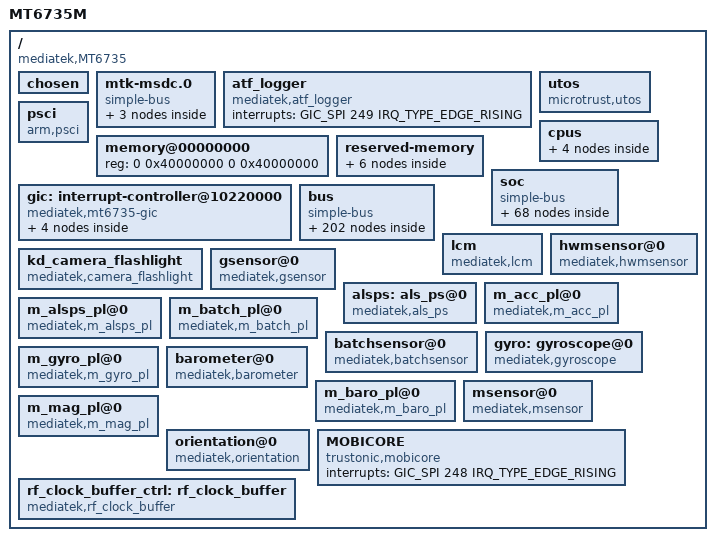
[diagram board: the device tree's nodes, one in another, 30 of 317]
/*
 * Mediatek's MT6735M SoC device tree source
 *
 * Copyright (c) 2013 MediaTek Co., Ltd.
 *              http://www.mediatek.com
 *
 */
#include <dt-bindings/interrupt-controller/arm-gic.h>
#include <dt-bindings/interrupt-controller/irq.h>
#include "mt6735m-pinfunc.h"
#include <dt-bindings/mmc/mt67xx-msdc.h>
#include <generated/autoconf.h>

/ {
	model = "MT6735M";
	compatible = "mediatek,MT6735";
	interrupt-parent = <&gic>;
	#address-cells = <2>;
	#size-cells = <2>;

	/* chosen */
		chosen {
			bootargs = "console=tty0 console=ttyMT0,921600n1 root=/dev/ram \
			initrd=0x44000000,0x1000000 loglevel=8 androidboot.hardware=mt6735";
		};

	/* Do not put any bus before mtk-msdc, because it should be mtk-msdc.0 for partition device node usage */
	/*workaround for .0*/
	mtk-msdc.0 {
				compatible = "simple-bus";
				#address-cells = <1>;
				#size-cells = <1>;
				ranges = <0 0 0 0xffffffff>;

				mmc0: msdc0@11230000{
						compatible = "mediatek,mt6735m-mmc";
						reg = <0x11230000 0x10000  /* MSDC0_BASE   */
							0x10000e84 0x2>;    /* FPGA PWR_GPIO, PWR_GPIO_EO */
						interrupts = <GIC_SPI 79 IRQ_TYPE_LEVEL_LOW>;
						status = "disabled";
				};

				mmc1: msdc1@11240000{
						compatible = "mediatek,mt6735m-mmc";
						reg = <0x11240000 0x10000  /* MSDC1_BASE   */
							0x10000e84 0x2>;    /* FPGA PWR_GPIO, PWR_GPIO_EO */
						interrupts = <GIC_SPI 80 IRQ_TYPE_LEVEL_LOW>;
						status = "disabled";
				};

	/* only used for old way of DCT, can be removed in new platform */
	msdc1_ins: default {
		compatible = "mediatek, msdc1_ins-eint";
	};
	};

	/* ATF logger SW IRQ number 281 = 32 + 249 */
	atf_logger {
		compatible = "mediatek,atf_logger";
		interrupts = <GIC_SPI 249 IRQ_TYPE_EDGE_RISING>;
	};

	utos {
		compatible = "microtrust,utos";
		interrupts = <GIC_SPI 244 IRQ_TYPE_EDGE_RISING>,
			<GIC_SPI 245 IRQ_TYPE_EDGE_RISING>,
			<GIC_SPI 246 IRQ_TYPE_EDGE_RISING>,
			<GIC_SPI 250 IRQ_TYPE_EDGE_RISING>,
			<GIC_SPI 251 IRQ_TYPE_EDGE_RISING>,
			<GIC_SPI 252 IRQ_TYPE_EDGE_RISING>,
			<GIC_SPI 253 IRQ_TYPE_EDGE_RISING>,
			<GIC_SPI 255 IRQ_TYPE_EDGE_RISING>;
	};

	psci {
		compatible	= "arm,psci";
		method		= "smc";
		cpu_suspend	= <0x84000001>;
		cpu_off		= <0x84000002>;
		cpu_on		= <0x84000003>;
		affinity_info	= <0x84000004>;
	};

	cpus {
		#address-cells = <1>;
		#size-cells = <0>;
/*		enable-method = "mediatek,mt6735-smp"; */

		cpu0: cpu@000 {
			device_type = "cpu";
			compatible = "arm,cortex-a53";
			reg = <0x000>;
			enable-method = "spin-table";
			cpu-release-addr = <0x0 0x40000200>;
			clock-frequency = <1000000000>;
		};

		cpu1: cpu@001 {
			device_type = "cpu";
			compatible = "arm,cortex-a53";
			reg = <0x001>;
			enable-method = "spin-table";
			cpu-release-addr = <0x0 0x40000200>;
			clock-frequency = <1000000000>;
		};

		cpu2: cpu@002 {
			device_type = "cpu";
			compatible = "arm,cortex-a53";
			reg = <0x002>;
			enable-method = "spin-table";
			cpu-release-addr = <0x0 0x40000200>;
			clock-frequency = <1000000000>;
		};

		cpu3: cpu@003 {
			device_type = "cpu";
			compatible = "arm,cortex-a53";
			reg = <0x003>;
			enable-method = "spin-table";
			cpu-release-addr = <0x0 0x40000200>;
			clock-frequency = <1000000000>;
		};
	};

	memory@00000000 {
		device_type = "memory";
		reg = <0 0x40000000 0 0x40000000>;
	};


		reserved-memory {
				#address-cells = <2>;
				#size-cells = <2>;
				ranges;

				/* reserve 192KB at DRAM start + 48MB */
				atf-reserved-memory@43000000 {
						compatible = "mediatek,mt6735-atf-reserved-memory",
						"mediatek,mt6735m-atf-reserved-memory",
						"mediatek,mt6753-atf-reserved-memory";
						no-map;
						reg = <0 0x43000000 0 0x30000>;
				};

		reserve-memory-ccci_md1 {
						compatible = "mediatek,reserve-memory-ccci_md1";
						no-map;
						size = <0 0x3810000>; // md_size+smem_size
						alignment = <0 0x2000000>;
						alloc-ranges = <0 0x40000000 0 0xC0000000>;
				};

				consys-reserve-memory {
						compatible = "mediatek,consys-reserve-memory";
						no-map;
						size = <0 0x100000>;
						alignment = <0 0x200000>;
				};

				ram_console-reserved-memory@43f00000 {
						compatible = "mediatek,ram_console";
						reg = <0 0x43f00000 0 0x10000>;
				};

				minirdump-reserved-memory@43ff0000 {
						compatible = "mediatek, minirdump";
						reg = <0 0x43ff0000 0 0x10000>;
				};

				pstore-reserved-memory@43f10000 {
						compatible = "mediatek,pstore";
						reg = <0 0x43f10000 0 0xe0000>;
				};
		};

		gic: interrupt-controller@10220000 {
				compatible = "mediatek,mt6735-gic";
				#interrupt-cells = <3>;
				#address-cells = <0>;
				interrupt-controller;
				reg = <0 0x10221000 0 0x1000>,
					<0 0x10222000 0 0x1000>,
					<0 0x10200620 0 0x1000>;

				mediatek,wdt_irq = <160>;

				gic-cpuif@0 {
					compatible = "arm,gic-cpuif";
					cpuif-id = <0>;
					cpu = <&cpu0>;
				};

				gic-cpuif@1 {
					compatible = "arm,gic-cpuif";
					cpuif-id = <1>;
					cpu = <&cpu1>;
				};

				gic-cpuif@2 {
					compatible = "arm,gic-cpuif";
					cpuif-id = <2>;
					cpu = <&cpu2>;
				};

				gic-cpuif@3 {
					compatible = "arm,gic-cpuif";
					cpuif-id = <3>;
					cpu = <&cpu3>;
				};

		};

	soc {
		compatible = "simple-bus";
		#address-cells = <1>;
		#size-cells = <1>;
		ranges = <0 0 0 0xffffffff>;

		cpuxgpt: cpuxgpt@10200000 {
			compatible = "mediatek,mt6735-cpuxgpt";
			reg = <0x10200000 0x1000>;
			interrupts = <GIC_SPI 64 IRQ_TYPE_LEVEL_HIGH>,
				<GIC_SPI 65 IRQ_TYPE_LEVEL_HIGH>,
				<GIC_SPI 66 IRQ_TYPE_LEVEL_HIGH>,
				<GIC_SPI 67 IRQ_TYPE_LEVEL_HIGH>,
				<GIC_SPI 68 IRQ_TYPE_LEVEL_HIGH>,
				<GIC_SPI 69 IRQ_TYPE_LEVEL_HIGH>,
				<GIC_SPI 70 IRQ_TYPE_LEVEL_HIGH>,
				<GIC_SPI 71 IRQ_TYPE_LEVEL_HIGH>;
		};

		apxgpt: apxgpt@10004000 {
			compatible = "mediatek,mt6735-apxgpt";
			reg = <0x10004000 0x1000>;
			interrupts = <GIC_SPI 152 IRQ_TYPE_LEVEL_LOW>;
			clock-frequency = <13000000>;
		};

		ledrgb: ledrgb {
			compatible = "mediatek,mt6735-led-rgb";
		};
		fingerprint: fingerprint {
			compatible = "mediatek,fingerprint";
		};

		hall_1: hall_1 {
			compatible = "mediatek,hall";
		};

		camera_flashlight: camera_flashlight {
			compatible = "mediatek,camera_flashlight";
		};


		pmu {
			compatible = "arm,cortex-a7-pmu";
			interrupts = <GIC_SPI 8 IRQ_TYPE_LEVEL_LOW>,
				<GIC_SPI 9 IRQ_TYPE_LEVEL_LOW>,
				<GIC_SPI 10 IRQ_TYPE_LEVEL_LOW>,
				<GIC_SPI 11 IRQ_TYPE_LEVEL_LOW>;
			interrupt-affinity = <&cpu0>,
					     <&cpu1>,
					     <&cpu2>,
					     <&cpu3>;
		};

		timer {
			compatible = "arm,armv8-timer";
			interrupts = <GIC_PPI 13 IRQ_TYPE_LEVEL_LOW>, /*Secure Physical Timer Event*/
				<GIC_PPI 14 IRQ_TYPE_LEVEL_LOW>, /*Non-Secure Physical Timer Event*/
				<GIC_PPI 11 IRQ_TYPE_LEVEL_LOW>, /*Virtual Timer Event*/
				<GIC_PPI 10 IRQ_TYPE_LEVEL_LOW>; /*Hypervisor Timer Event*/
				clock-frequency = <13000000>;
		};

		mt_pmic_regulator {
			compatible = "mediatek,mt_pmic";
			/*reg = <0x01>*/
			buck_regulators {
			compatible = "mediatek,mt_pmic_buck_regulators";
				mt_pmic_vpa_buck_reg: buck_vpa {
					regulator-name = "vpa";
					regulator-min-microvolt = <500000>;
					regulator-max-microvolt = <3650000>;
					regulator-ramp-delay = <50000>;
					regulator-enable-ramp-delay = <180>;
				};
				mt_pmic_vproc_buck_reg: buck_vproc {
					regulator-name = "vproc";
					regulator-min-microvolt = <600000>;
					regulator-max-microvolt = <1393750>;
					regulator-ramp-delay = <6250>;
					regulator-enable-ramp-delay = <180>;
					regulator-always-on;
					regulator-boot-on;
				};
				mt_pmic_vcore1_buck_reg: buck_vcore1 {
					regulator-name = "vcore1";
					regulator-min-microvolt = <600000>;
					regulator-max-microvolt = <1393750>;
					regulator-ramp-delay = <6250>;
					regulator-enable-ramp-delay = <180>;
					regulator-always-on;
					regulator-boot-on;
				};
				mt_pmic_vsys22_buck_reg: buck_vsys22 {
					regulator-name = "vsys22";
					regulator-min-microvolt = <1200000>;
					regulator-max-microvolt = <1993750>;
					regulator-ramp-delay = <6250>;
					regulator-enable-ramp-delay = <180>;
					regulator-always-on;
					regulator-boot-on;
				};
				mt_pmic_vlte_buck_reg: buck_vlte {
					regulator-name = "vlte";
					regulator-min-microvolt = <600000>;
					regulator-max-microvolt = <1393750>;
					regulator-ramp-delay = <6250>;
					regulator-enable-ramp-delay = <180>;
					regulator-always-on;
					regulator-boot-on;
				};
			};	/* End of buck_regulators */
			ldo_regulators {
				compatible = "mediatek,mt_pmic_ldo_regulators";
				mt_pmic_vaux18_ldo_reg: ldo_vaux18 {
					regulator-name = "vaux18";
					regulator-min-microvolt = <1800000>;
					regulator-max-microvolt = <1800000>;
					regulator-enable-ramp-delay = <264>;
					regulator-boot-on;
				};
				mt_pmic_vtcxo_0_ldo_reg: ldo_vtcxo_0 {
					regulator-name = "vtcxo_0";
					regulator-min-microvolt = <2800000>;
					regulator-max-microvolt = <2800000>;
					regulator-enable-ramp-delay = <110>;
					regulator-boot-on;
				};
				mt_pmic_vtcxo_1_ldo_reg: ldo_vtcxo_1 {
					regulator-name = "vtcxo_1";
					regulator-min-microvolt = <2800000>;
					regulator-max-microvolt = <2800000>;
					regulator-enable-ramp-delay = <110>;
				};
				mt_pmic_vaud28_ldo_reg: ldo_vaud28 {
					regulator-name = "vaud28";
					regulator-min-microvolt = <2800000>;
					regulator-max-microvolt = <2800000>;
					regulator-enable-ramp-delay = <264>;
					regulator-boot-on;
				};
				mt_pmic_vcn28_ldo_reg: ldo_vcn28 {
					regulator-name = "vcn28";
					regulator-min-microvolt = <2800000>;
					regulator-max-microvolt = <2800000>;
					regulator-enable-ramp-delay = <264>;
				};
				mt_pmic_vcama_ldo_reg: ldo_vcama {
					regulator-name = "vcama";
					regulator-min-microvolt = <1500000>;
					regulator-max-microvolt = <2800000>;
					regulator-enable-ramp-delay = <264>;
				};
				mt_pmic_vcn33_bt_ldo_reg: ldo_vcn33_bt {
					regulator-name = "vcn33_bt";
					regulator-min-microvolt = <3300000>;
					regulator-max-microvolt = <3600000>;
					regulator-enable-ramp-delay = <264>;
				};
				mt_pmic_vcn33_wifi_ldo_reg: ldo_vcn33_wifi {
					regulator-name = "vcn33_wifi";
					regulator-min-microvolt = <3300000>;
					regulator-max-microvolt = <3600000>;
					regulator-enable-ramp-delay = <264>;
				};
				mt_pmic_vusb33_ldo_reg: ldo_vusb33 {
					regulator-name = "vusb33";
					regulator-min-microvolt = <3300000>;
					regulator-max-microvolt = <3300000>;
					regulator-enable-ramp-delay = <264>;
					regulator-boot-on;
				};
				mt_pmic_vefuse_ldo_reg: ldo_vefuse {
					regulator-name = "vefuse";
					regulator-min-microvolt = <1800000>;
					regulator-max-microvolt = <2200000>;
					regulator-enable-ramp-delay = <264>;
				};
				mt_pmic_vsim1_ldo_reg: ldo_vsim1 {
					regulator-name = "vsim1";
					regulator-min-microvolt = <1700000>;
					regulator-max-microvolt = <2100000>;
					regulator-enable-ramp-delay = <264>;
				};
				mt_pmic_vsim2_ldo_reg: ldo_vsim2 {
					regulator-name = "vsim2";
					regulator-min-microvolt = <1700000>;
					regulator-max-microvolt = <2100000>;
					regulator-enable-ramp-delay = <264>;
				};
				mt_pmic_vemc33_ldo_reg: ldo_vemc_3v3 {
					regulator-name = "vemc_3v3";
					regulator-min-microvolt = <1800000>;
					regulator-max-microvolt = <3300000>;
					regulator-enable-ramp-delay = <264>;
					regulator-boot-on;
				};
				mt_pmic_vmch_ldo_reg: ldo_vmch {
					regulator-name = "vmch";
					regulator-min-microvolt = <2900000>;
					regulator-max-microvolt = <3300000>;
					regulator-enable-ramp-delay = <44>;
				};
				mt_pmic_vtref_ldo_reg: ldo_vtref {
					regulator-name = "vtref";
					regulator-min-microvolt = <1800000>;
					regulator-max-microvolt = <1800000>;
					regulator-enable-ramp-delay = <240>;
				};
				mt_pmic_vmc_ldo_reg: ldo_vmc {
					regulator-name = "vmc";
					regulator-min-microvolt = <1800000>;
					regulator-max-microvolt = <3300000>;
					regulator-enable-ramp-delay = <44>;
				};
				mt_pmic_vcam_af_ldo_reg: ldo_vcamaf {
					regulator-name = "vcamaf";
					regulator-min-microvolt = <1200000>;
					regulator-max-microvolt = <3300000>;
					regulator-enable-ramp-delay = <264>;
				};
				mt_pmic_vio28_ldo_reg: ldo_vio28 {
					regulator-name = "vio28";
					regulator-min-microvolt = <2800000>;
					regulator-max-microvolt = <2800000>;
					regulator-enable-ramp-delay = <264>;
					regulator-boot-on;
				};
				mt_pmic_vgp1_ldo_reg: ldo_vgp1 {
					regulator-name = "vgp1";
					regulator-min-microvolt = <1200000>;
					regulator-max-microvolt = <3300000>;
					regulator-enable-ramp-delay = <264>;
				};
				mt_pmic_vibr_ldo_reg: ldo_vibr {
					regulator-name = "vibr";
					regulator-min-microvolt = <1200000>;
					regulator-max-microvolt = <3300000>;
					regulator-enable-ramp-delay = <44>;
				};
				mt_pmic_vcamd_ldo_reg: ldo_vcamd {
					regulator-name = "vcamd";
					regulator-min-microvolt = <900000>;
					regulator-max-microvolt = <1500000>;
					regulator-enable-ramp-delay = <264>;
				};
				mt_pmic_vrf18_0_ldo_reg: ldo_vrf18_0 {
					regulator-name = "vrf18_0";
					regulator-min-microvolt = <1825000>;
					regulator-max-microvolt = <1825000>;
					regulator-enable-ramp-delay = <220>;
				};
				mt_pmic_vrf18_1_ldo_reg: ldo_vrf18_1 {
					regulator-name = "vrf18_1";
					regulator-min-microvolt = <1200000>;
					regulator-max-microvolt = <1825000>;
					regulator-enable-ramp-delay = <220>;
				};
				mt_pmic_vio18_ldo_reg: ldo_vio18 {
					regulator-name = "vio18";
					regulator-min-microvolt = <1800000>;
					regulator-max-microvolt = <1800000>;
					regulator-enable-ramp-delay = <264>;
					regulator-boot-on;
				};
				mt_pmic_vcn18_ldo_reg: ldo_vcn18 {
					regulator-name = "vcn18";
					regulator-min-microvolt = <1800000>;
					regulator-max-microvolt = <1800000>;
					regulator-enable-ramp-delay = <44>;
				};
				mt_pmic_vcam_io_ldo_reg: ldo_vcamio {
					regulator-name = "vcamio";
					regulator-min-microvolt = <1200000>;
					regulator-max-microvolt = <1800000>;
					regulator-enable-ramp-delay = <220>;
				};
				mt_pmic_vsram_ldo_reg: ldo_vsram {
					regulator-name = "vsram";
					regulator-min-microvolt = <700000>;
					regulator-max-microvolt = <1493750>;
					regulator-enable-ramp-delay = <220>;
					regulator-ramp-delay = <6250>;
					regulator-boot-on;
				};
				mt_pmic_vm_ldo_reg: ldo_vm {
					regulator-name = "vm";
					regulator-min-microvolt = <1240000>;
					regulator-max-microvolt = <1540000>;
					regulator-enable-ramp-delay = <264>;
					regulator-boot-on;
				};
			};/* End of ldo_regulators */
			regulators_supply {
				compatible = "mediatek,mt_pmic_regulator_supply";
				vaux18-supply = <&mt_pmic_vaux18_ldo_reg>;
				vtcxo_0-supply = <&mt_pmic_vtcxo_0_ldo_reg>;
				vtcxo_1-supply = <&mt_pmic_vtcxo_1_ldo_reg>;
				vaud28-supply = <&mt_pmic_vaud28_ldo_reg>;
				vefuse-supply = <&mt_pmic_vefuse_ldo_reg>;
				vsim1-supply = <&mt_pmic_vsim1_ldo_reg>;
				vsim2-supply = <&mt_pmic_vsim2_ldo_reg>;
				vemc_3v3-supply = <&mt_pmic_vemc33_ldo_reg>;
				vmch-supply = <&mt_pmic_vmch_ldo_reg>;
				vtref-supply = <&mt_pmic_vtref_ldo_reg>;
				vmc-supply = <&mt_pmic_vmc_ldo_reg>;
				vio28-supply = <&mt_pmic_vio28_ldo_reg>;
				vibr-supply = <&mt_pmic_vibr_ldo_reg>;
				vrf18_0-supply = <&mt_pmic_vrf18_0_ldo_reg>;
				vrf18_1-supply = <&mt_pmic_vrf18_1_ldo_reg>;
				vio18-supply = <&mt_pmic_vio18_ldo_reg>;
				vsram-supply = <&mt_pmic_vsram_ldo_reg>;
				vm-supply = <&mt_pmic_vm_ldo_reg>;

			};/* End of regulators_supply */
		};/* End of mt_pmic_regulator */
		toprgu: toprgu@10212000 {
			compatible = "mediatek,mt6735-rgu";
			reg = <0x10212000 0x1000>;
			interrupts = <GIC_SPI 128 IRQ_TYPE_EDGE_FALLING>;
		};

		mcu_biu: mcu_biu@10300000 {
			compatible = "mediatek,mt6735-mcu_biu";
			reg = <0x10300000 0x8000>;
		};

		gpio_usage_mapping:gpio {
			compatible = "mediatek,gpio_usage_mapping";
		};

		gpio: gpio@10211000 {
			compatible = "mediatek,gpio";
			reg = <0x10211000 0x1000>;
		};

		dramc_nao: dramc_nao@1020e000 {
			compatible = "mediatek,mt6735-dramc_nao";
			reg = <0x1020e000 0x1000>;
		};

		ddrphy: ddrphy@10213000 {
			compatible = "mediatek,mt6735-ddrphy";
			reg = <0x10213000 0x1000>;
		};

		dramc: dramc@10214000 {
			compatible = "mediatek,mt6735-dramc";
			reg = <0x10214000 0x1000>;
			/*clocks = <&infrasys INFRA_GCE>;*/
			clock-names = "infra-cqdma";
		};

		keypad: keypad@10003000 {
			compatible = "mediatek,mt6735-keypad",
					"mediatek,mt6735m-keypad";
			reg = <0x10003000 0x1000>;
			interrupts = <GIC_SPI 164 IRQ_TYPE_EDGE_FALLING>;
		};

		apirtx:irtx@11011000 {
			compatible = "mediatek,irtx";
			reg = <0x11011000 0x1000>;
			interrupts = <GIC_SPI 124 IRQ_TYPE_LEVEL_HIGH>;
			pwm_ch = <0>;
		};

		apuart0: apuart0@11002000 {
			cell-index = <0>;
			compatible = "mediatek,mt6735-uart";
			reg = <0x11002000 0x1000>, /* UART base */
				  <0x11000380 0x1000>, /* DMA Tx base */
				  <0x11000400 0x80>; /* DMA Rx base */
			interrupts = <GIC_SPI 91 IRQ_TYPE_LEVEL_LOW>, /* UART IRQ */
						 <GIC_SPI 103 IRQ_TYPE_LEVEL_LOW>, /* DMA Tx IRQ */
						 <GIC_SPI 104 IRQ_TYPE_LEVEL_LOW>; /* DMA Rx IRQ */
		};

		apuart1: apuart1@11003000 {
			cell-index = <1>;
			compatible = "mediatek,mt6735-uart";
			reg = <0x11003000 0x1000>, /* UART base */
				  <0x11000480 0x80>, /* DMA Tx base */
				  <0x11000500 0x80>; /* DMA Rx base */
			interrupts = <GIC_SPI 92 IRQ_TYPE_LEVEL_LOW>, /* UART IRQ */
						 <GIC_SPI 105 IRQ_TYPE_LEVEL_LOW>, /* DMA Tx IRQ */
						 <GIC_SPI 106 IRQ_TYPE_LEVEL_LOW>; /* DMA Rx IRQ */
		};

		apuart2: apuart2@11004000 {
			cell-index = <2>;
			compatible = "mediatek,mt6735-uart";
			reg = <0x11004000 0x1000>, /* UART base */
				  <0x11000580 0x80>, /* DMA Tx base */
				  <0x11000600 0x80>; /* DMA Rx base */
			interrupts = <GIC_SPI 93 IRQ_TYPE_LEVEL_LOW>, /* UART IRQ */
						 <GIC_SPI 107 IRQ_TYPE_LEVEL_LOW>, /* DMA Tx IRQ */
						 <GIC_SPI 108 IRQ_TYPE_LEVEL_LOW>; /* DMA Rx IRQ */
		};

		apuart3: apuart3@11005000 {
			cell-index = <3>;
			compatible = "mediatek,mt6735-uart";
			reg = <0x11005000 0x1000>, /* UART base */
				  <0x11000680 0x80>, /* DMA Tx base */
				  <0x11000700 0x80>; /* DMA Rx base */
			interrupts = <GIC_SPI 94 IRQ_TYPE_LEVEL_LOW>, /* UART IRQ */
						 <GIC_SPI 109 IRQ_TYPE_LEVEL_LOW>, /* DMA Tx IRQ */
						 <GIC_SPI 110 IRQ_TYPE_LEVEL_LOW>; /* DMA Rx IRQ */
		};
		spi0:spi@1100a000 {
			compatible = "mediatek,mt6735m-spi";
			cell-index = <0>;
			spi-padmacro = <0>;
			reg = <0x1100a000 0x1000>;
			interrupts = <GIC_SPI 118 IRQ_TYPE_LEVEL_LOW>;
		};

		btif_tx:btif_tx@11000780 {
			compatible = "mediatek,btif_tx";
			reg = <0x11000780 0x80>;
			interrupts = <GIC_SPI 111 IRQ_TYPE_LEVEL_LOW>;
		};
		btif_rx:btif_rx@11000800 {
			compatible = "mediatek,btif_rx";
			reg = <0x11000800 0x80>;
			interrupts = <GIC_SPI 112 IRQ_TYPE_LEVEL_LOW>;
		};
		btif:btif@1100c000 {
			compatible = "mediatek,btif";
			reg = <0x1100c000 0x1000>;
			interrupts = <GIC_SPI 90 IRQ_TYPE_LEVEL_LOW>;
		};/* End of btif */

		consys:consys@18070000 {
			compatible = "mediatek,mt6735m-consys",
						 "mediatek,mt6735-consys";
			reg = <0x18070000 0x0200>,  /*CONN_MCU_CONFIG_BASE      */
			      <0x10212000 0x0100>,  /*AP_RGU_BASE               */
			      <0x10000000 0x2000>,  /*TOPCKGEN_BASE             */
			      <0x10006000 0x1000>;  /*SPM_BASE                  */
			interrupts = <GIC_SPI 227 IRQ_TYPE_LEVEL_LOW>, /* BGF_EINT */
						 <GIC_SPI 225 IRQ_TYPE_LEVEL_LOW>; /* WDT_EINT */
			vcn18-supply = <&mt_pmic_vcn18_ldo_reg>;
			vcn28-supply = <&mt_pmic_vcn28_ldo_reg>;
			vcn33_bt-supply = <&mt_pmic_vcn33_bt_ldo_reg>;
			vcn33_wifi-supply = <&mt_pmic_vcn33_wifi_ldo_reg>;
		};

		hacc:hacc@10008000 {
			compatible = "mediatek,hacc";
			reg = <0x10008000 0x1000>;
			interrupts = <GIC_SPI 174 IRQ_TYPE_LEVEL_LOW>;
		};
		als: als {
			compatible = "mediatek, als-eint";
		};

		gse_1: gse_1 {
			compatible = "mediatek, gse_1-eint";
			status = "disabled";
		};
		ext_buck_oc: ext_buck_oc {
			compatible = "mediatek, ext_buck_oc-eint";
			status = "disabled";
		};
		swtp: swtp {
			compatible = "mediatek, swtp-eint";
		};
	};

	bus {
		compatible = "simple-bus";
		#address-cells = <1>;
		#size-cells = <1>;
		ranges = <0 0 0 0xffffffff>;

		INFRACFG_AO@0x10000000 {
			compatible = "mediatek,INFRACFG_AO";
			reg = <0x10000000 0x1000>;
		};

		usb2jtag: usb2jtag@10000000 {
			compatible = "mediatek,usb2jtag_v1";
			reg = <0x10000000 0x1000>, <0x11210000 0x1000>;
		};

		PWRAP@0x10001000 {
			compatible = "mediatek,PWRAP";
			reg = <0x10001000 0x1000>;
			interrupts = <0 163 0x4>;
		};

		PERICFG@0x10002000 {
			compatible = "mediatek,PERICFG";
			reg = <0x10002000 0x1000>;
		};

		FHCTL@0x10209F00 {
			compatible = "mediatek,FHCTL";
			reg = <0x10209F00 0x100>;
		};
		KP@0x10003000 {
			compatible = "mediatek,KP";
			reg = <0x10003000 0x1000>;
			interrupts = <0 164 0x2>;
		};



		eintc: eintc@10005000 {
			compatible = "mediatek,mt-eic";
			reg = <0x10005000 0x1000>;
			interrupts = <GIC_SPI 153 IRQ_TYPE_LEVEL_HIGH>;

			#interrupt-cells = <2>;
			interrupt-controller;

			mediatek,max_eint_num = <213>;
			mediatek,mapping_table_entry = <0>;

			mediatek,debtime_setting_entry = <10>;
			mediatek,debtime_setting_array	= <0 125>,
							<1 250>,
							<2 500>,
							<3 1000>,
							<4 16000>,
							<5 32000>,
							<6 64000>,
							<7 128000>,
							<8 256000>,
							<9 512000>;
		};

				SLEEP@0x10006000 {
						compatible = "mediatek,SLEEP";
						reg = <0x10006000 0x1000>;
						interrupts = <0 165 0x8>,
												 <0 166 0x8>,
												 <0 167 0x8>,
												 <0 168 0x8>;
				};

		DEVAPC_AO@10007000 {
			compatible = "mediatek,DEVAPC_AO";
			reg = <0x10007000 0x1000>;
		};

		RSVD@0x10009000 {
			compatible = "mediatek,RSVD";
			reg = <0x10009000 0x1000>;
		};


		bat_meter: bat_meter {
			compatible = "mediatek,bat_meter";
			/* cust_battery_meter.h */
			/* ADC resistor  */
			r_bat_sense = <4 >;
			r_i_sense = <4 >;
			r_charger_1 = <330 >;
			r_charger_2 = <39 >;
			temperature_t0 = <110 >;
			temperature_t1 = <0 >;
			temperature_t2 = <25 >;
			temperature_t3 = <50 >;
			temperature_t = <255 >;	/* this should be fixed, never change the value */
			fg_meter_resistance = <0 >;

			/* Qmax for 0mA */
			q_max_pos_50 = <2409 >;
			q_max_pos_25 = <2331 >;
			q_max_pos_0 = <2391 >;
			q_max_neg_10 = <2390 >;
			/* Qmax for 400mA, said high current */
			q_max_pos_50_h_current = <2392 >;
			q_max_pos_25_h_current = <2285 >;
			q_max_pos_0_h_current = <1733 >;
			q_max_neg_10_h_current = <1355 >;
			/* Discharge percentage, 1: D5, 0: D2 */
			oam_d5 = <1 >;

			change_tracking_point = <1 >;
			/* SW OCV tracking setting */
			cust_tracking_point = <1 >;
			cust_r_sense = <68 >;
			cust_hw_cc = <0 >;
			aging_tuning_value = <103 >;
			cust_r_fg_offset = <0 >;
			ocv_board_compesate = <0 >;
			r_fg_board_base = <1000 >;
			r_fg_board_slope = <1000 >;
			car_tune_value = <92 >;

			/* HW Fuel gague  */
			current_detect_r_fg = <10 >;	/* Unit: mA */
			minerroroffset = <1000 >;
			fg_vbat_average_size = <18 >;
			r_fg_value = <10 >;	/* Unit: mOhm */

			cust_poweron_delta_capacity_tolrance = <30 >;
			cust_poweron_low_capacity_tolrance = <5 >;
			cust_poweron_max_vbat_tolrance = <90 >;
			cust_poweron_delta_vbat_tolrance = <30 >;
			cust_poweron_delta_hw_sw_ocv_capacity_tolrance = <10 >;

			/* Fixed battery temperature */
			fixed_tbat_25 = <1 >;
			/* Dynamic change wake up period of battery thread when suspend */
			vbat_normal_wakeup = <3600 >;	/* Unit: mV */
			vbat_low_power_wakeup = <3500 >;	/* Unit: mV */
			normal_wakeup_period = <5400 >;	/* Unit: second */
			low_power_wakeup_period = <300 >;	/* Unit: second */
			close_poweroff_wakeup_period = <30 >;	/* Unit: second */

			rbat_pull_up_r = <16900 >;
			rbat_pull_up_volt = <1800 >;


			batt_temperature_table_num = <17 >;
			batt_temperature_table = <
			    (-20) 68237
			    (-15) 53650
			    (-10) 42506
			    (-5) 33892
			    0 27219
			    5 22021
			    10 17926
			    15 14674
			    20 12081
			    25 10000 30 8315 35 6948 40 5834 45 4917 50 4161 55 3535 60 3014 >;
			battery_profile_t0_num = <100 >;
			battery_profile_t0 = <0	4312
				1	4284
				2	4253
				3	4240
				4	4229
				5	4214
				6	4204
				7	4193
				8	4169
				9	4157
				10	4148
				11	4136
				12	4133
				13	4117
				14	4105
				15	4096
				16	4091
				17	4086
			    18	4079
			    19	4048
			    20	4036
			    21	4028
			    22	4020
			    23	4003
			    24	3978
			    25	3973
			    26	3968
			    27	3965
			    28	3960
			    29	3951
			    30	3947
			    31	3943
			    32	3940
			    33	3931
			    34	3906
			    35	3895
			    36	3886
			    37	3883
			    38	3879
			    39	3873
			    40	3868
			    41	3864
			    42	3860
			    43	3857
			    44	3849
			    45	3845
			    46	3843
			    47	3838
			    48	3834
			    49	3827
			    50	3821
			    51	3816
			    52	3811
			    53	3807
			    55	3800
			    56	3798
			    57	3796
			    58	3793
			    59	3790
			    60	3788
			    61	3788
			    62	3785
			    63	3785
			    64	3780
			    65	3779
			    66	3777
			    67	3776
			    68	3771
			    69	3769
			    70	3767
			    71	3766
			    72	3765
			    73	3761
			    74	3760
			    75	3759
			    76	3756
			    77	3751
			    78	3743
			    79	3740
			    80	3738
			    81	3733
			    82	3724
			    83	3721
			    84	3717
			    85	3713
			    86	3712
			    87	3705
			    88	3702
			    89	3695
			    90	3689
			    91	3684
			    92	3676
			    93	3663
			    94	3651
			    95	3638
			    96	3626
			    97	3612
			    98	3566
			    99	3523
			    100 3500 >;
			battery_profile_t1_num = <100 >;
			battery_profile_t1 = <0	4333
				1	4312
				2	4296
				3	4270
				4	4258
				5	4247
				6	4237
				7	4227
				8	4208
				9	4198
				10	4188
				11	4179
				12	4160
				13	4152
			    14	4143
			    15	4133
			    16	4125
			    17	4111
			    18	4103
			    19	4097
			    20	4090
			    21	4082
			    22	4070
			    23	4044
			    24	4031
			    25	4019
			    26	4008
			    27	3989
			    28	3982
			    29	3974
			    30	3968
			    31	3962
			    32	3956
			    33	3945
			    34	3938
			    35	3931
			    36	3925
			    37	3912
			    38	3905
			    39	3899
			    40	3894
			    41	3888
			    42	3883
			    43	3872
			    44	3867
			    45	3862
			    46	3858
			    47	3848
			    48	3844
			    49	3841
			    50	3837
			    51	3834
			    52	3827
			    53	3823
			    54	3819
			    55	3817
			    56	3814
			    57	3811
			    58	3808
			    59	3806
			    60	3805
			    61	3803
			    62	3801
			    63	3798
			    64	3797
			    65	3795
			    66	3793
			    67	3790
			    68	3788
			    69	3787
			    70	3786
			    71	3783
			    72	3782
			    73	3779
			    74	3776
			    75	3774
			    76	3771
			    77	3765
			    78	3761
			    80	3755
			    81	3751
			    82	3744
			    83	3740
			    84	3734
			    85	3729
			    86	3724
			    87	3714
			    88	3709
			    89	3705
			    90	3702
			    91	3699
			    92	3693
			    93	3689
			    94	3683
			    95	3674
			    96	3662
			    97	3611
			    98	3573
			    99	3521
			    100 3500 >;
			battery_profile_t2_num = <100 >;
			battery_profile_t2 = <0 4329
			    2   4303
			    4   4282
			    5   4261
			    7   4241
			    9   4221
			    11  4202
			    13  4183
			    15  4164
			    16  4146
			    18  4127
			    20  4109
			    22  4091
			    24  4076
			    25  4067
			    27  4048
			    29  4017
			    31  3993
			    33  3979
			    34  3971
			    36  3963
			    38  3951
			    40  3937
			    42  3920
			    44  3900
			    45  3883
			    47  3869
			    49  3858
			    51  3847
			    53  3839
			    54  3830
			    56  3823
			    58  3816
			    60  3809
			    62  3803
			    64  3797
			    65  3792
			    67  3787
			    69  3783
			    71  3778
			    73  3772
			    74  3765
			    76  3758
			    78  3751
			    80  3745
			    82  3739
			    84  3731
			    85  3720
			    87  3710
			    89  3696
			    91  3689
			    93  3688
			    94  3685
			    96  3676
			    98  3620
			    100 3500
			    100 3500
			    100 3500
			    100 3500
                100 3500
			    100 3500
			    100 3500
			    100 3500
			    100 3500
			    100 3500
			    100 3500
			    100 3500
			    100 3500
			    100 3500
			    100 3500
			    100 3500
			    100 3500
			    100 3500
			    100 3500
			    100 3500
			    100 3500
			    100 3500
			    100 3500
			    100 3500
			    100 3500
			    100 3500
			    100 3500
			    100 3500
			    100 3500
			    100 3500
			    100 3500
			    100 3500
			    100 3500
			    100 3500
			    100 3500
			    100 3500
			    100 3500
			    100 3500
			    100 3500
			    100 3500
			    100 3500
			    100 3500
			    100 3500
			    100 3500
			    100 3500 >;
			battery_profile_t3_num = <100 >;
			battery_profile_t3 = <0 4339
				1   4327
				2   4315
				3   4294
				4   4284
				5   4275
			    6   4265
			    7   4246
			    8   4236
			    9   4227
			    10  4218
			    11  4209
			    12  4200
			    13  4182
			    14  4173
			    15  4163
			    16  4154
			    17  4136
			    18  4128
			    19  4120
			    20  4111
			    21  4094
			    22  4086
			    23  4076
			    24  4069
			    25  4061
			    26  4045
			    27  4039
			    28  4031
			    29  4022
			    30  4013
			    31  3999
			    32  3993
			    33  3987
			    34  3979
			    35  3973
			    36  3961
			    37  3955
			    38  3948
			    39  3941
			    40  3935
			    41  3924
			    42  3916
			    43  3906
			    44  3896
			    45  3878
			    46  3872
			    47  3865
			    48  3860
			    49  3854
			    50  3850
			    51  3842
			    52  3838
			    53  3834
			    54  3829
			    55  3822
			    56  3818
			    57  3814
			    58  3812
			    59  3810
			    60  3802
			    61  3798
			    62  3796
			    63  3793
			    64  3791
			    65  3786
			    66  3785
			    68  3780
			    69  3777
			    70  3772
			    71  3769
			    72  3765
			    73  3759
			    74  3751
			    75  3743
			    76  3739
			    77  3736
			    78  3733
			    79  3729
			    80  3723
			    81  3721
			    82  3717
			    83  3714
			    84  3707
			    85  3702
			    86  3697
			    87  3692
			    88  3687
			    89	3674
			    90  3672
			    91  3671
			    92  3671
			    93  3669
			    94  3667
			    95  3666
			    96  3659
			    97  3648
			    98  3590
			    99  3550
			    100 3500 >;

			r_profile_t0_num = <100 >;
			r_profile_t0 = <416  4312
				416  4284
				368  4253
				337  4240
				318  4229
				483  4214
				489  4204
				452  4193
				517  4169
				646  4157
				465  4148
				624  4136
				461  4133
				361  4117
				532  4105
				626  4096
				502  4091
				434  4086
				386  4079
				618  4048
				491  4036
				422  4028
				374  4020
				403  4003
				534  3978
				446  3973
				393  3968
				354  3965
				328  3960
				288  3951
				274  3947
				264  3943
				254  3940
				258  3931
				543  3906
			    653  3895
			    747  3886
			    787  3883
			    547  3879
			    411  3873
			    366  3868
			    333  3864
			    310  3860
			    291  3857
			    261  3849
			    251  3845
			    242  3843
			    233  3838
			    227  3834
			    231  3827
			    422  3821
			    584  3816
			    510  3811
			    667  3807
			    484  3800
			    434  3798
			    398  3796
			    473  3793
			    496  3790
			    440  3788
			    401  3788
			    520  3785
			    439  3785
			    526  3780
			    461  3779
			    414  3777
			    489  3776
			    803  3771
			    681  3769
			    571  3767
			    501  3766
			    452  3765
			    386  3761
			    363  3760
			    345  3759
			    465  3756
			    614  3751
			    851  3743
			    729  3740
			    611  3738
			    687  3733
			    735  3724
			    656  3721
			    779  3717
			    726  3713
			    634  3712
			    791  3705
			    486  3702
			    695  3695
			    842  3689
			    759  3684
			    661  3676
			    865  3663
			    995  3651
			    948  3638
			    818  3626
			    746  3612
			    664  3566
			    867  3523
			    1048 3500 >;

			r_profile_t1_num = <100 >;
			r_profile_t1 = <770  4333
				770  4312
				848  4296
				875  4270
				880  4258
				878  4247
				878  4237
				880  4227
				878  4208
				878  4198
				875  4188
				875  4179
				873  4160
				873  4152
				875  4143
				868  4133
				865  4125
				873  4111
				868  4103
				870  4097
				868  4090
				873  4082
				865  4070
				850  4044
				842  4031
				838  4019
				838  4008
				830  3989
				835  3982
				830  3974
				833  3968
				835  3962
			    835  3956
			    835  3945
			    833  3938
			    830  3931
			    830  3925
			    828  3912
			    823  3905
			    823  3899
			    825  3894
			    825  3888
			    825  3883
			    825  3872
			    830  3867
			    828  3862
			    828  3858
			    828  3848
			    833  3844
			    835  3841
			    838  3837
			    840  3834
			    848  3827
			    845  3823
			    848  3819
			    853  3817
			    855  3814
			    863  3811
			    865  3808
			    865  3806
			    873  3805
			    878  3803
			    880  3801
			    885  3798
			    893  3797
			    898  3795
			    898  3793
			    905  3790
			    913  3788
			    918  3787
			    928  3786
			    930  3783
			    940  3782
			    955  3779
			    965  3776
			    975  3774
			    980  3771
			    1003 3765
			    1008 3761
			    1038 3755
			    1050 3751
			    1083 3744
			    1098 3740
			    1113 3734
			    1133 3729
			    1150 3724
			    1200 3714
			    1225 3709
			    1253 3705
			    1288 3702
			    1315 3699
			    1390 3693
			    1433 3689
			    1473 3683
			    1513 3674
			    1558 3662
			    1625 3611
			    1665 3573
			    1703 3521
			    1750 3500 >;

			r_profile_t2_num = <100 >;
			r_profile_t2 = <204 4329
			    204 4303
			    209 4282
			    207 4261
			    207 4241
			    207 4221
			    207 4202
			    209 4183
			    209 4164
			    211 4146
			    211 4127
			    213 4109
			    216 4091
			    218 4076
			    231 4067
			    233 4048
			    224 4017
			    222 3993
			    229 3979
			    233 3971
			    240 3963
			    238 3951
			    236 3937
			    227 3920
			    211 3900
			    204 3883
			    202 3869
			    200 3858
			    198 3847
			    200 3839
			    200 3830
			    202 3823
			    202 3816
			    204 3809
			    207 3803
			    207 3797
			    209 3792
			    209 3787
			    211 3783
			    213 3778
			    209 3772
			    204 3765
			    202 3758
			    202 3751
			    202 3745
			    204 3739
			    209 3731
			    209 3720
			    213 3710
			    216 3696
			    216 3689
			    227 3688
			    238 3685
			    256 3676
			    262 3620
			    284 3500
			    336 3500
			    336 3500
			    336 3500
			    336 3500
				336 3500
			    336 3500
			    336 3500
			    336 3500
			    336 3500
			    336 3500
			    336 3500
			    336 3500
			    336 3500
			    336 3500
			    336 3500
			    336 3500
			    336 3500
			    336 3500
			    336 3500
			    336 3500
			    336 3500
			    336 3500
			    336 3500
			    336 3500
			    336 3500
			    336 3500
				336 3500
			    336 3500
			    336 3500
			    336 3500
			    336 3500
			    336 3500
			    336 3500
			    336 3500
			    336 3500
			    336 3500
			    336 3500
			    336 3500
			    336 3500
			    336 3500
			    336 3500
			    336 3500
			    336 3500
			    336 3500 >;

			r_profile_t3_num = <100 >;
			r_profile_t3 = <100 4339
				100 4327
				100 4315
				98  4294
				100 4284
				103 4275
			    103 4265
			    103 4246
			    103 4236
			    105 4227
			    103 4218
			    103 4209
			    108 4200
			    108 4182
			    110 4173
			    105 4163
			    105 4154
			    103 4136
			    105 4128
			    110 4120
			    110 4111
			    110 4094
			    108 4086
			    105 4076
			    105 4069
			    108 4061
			    108 4045
			    112 4039
			    110 4031
			    110 4022
			    113 4013
			    110 3999
			    113 3993
			    115 3987
			    110 3979
			    115 3973
			    118 3961
			    120 3955
			    118 3948
			    115 3941
			    115 3935
			    123 3924
			    120 3916
			    115 3906
			    110 3896
			    103 3878
			    108 3872
			    105 3865
			    105 3860
			    103 3854
			    100 3850
			    105 3842
			    105 3838
			    108 3834
			    103 3829
			    103 3822
			    103 3818
			    105 3814
			    105 3812
			    110 3810
			    105 3802
			    103 3798
			    105 3796
			    105 3793
			    105 3791
			    108 3786
			    113 3785
			    113 3780
			    110 3777
			    110 3772
			    110 3769
			    105 3765
			    105 3759
			    105 3751
			    103 3743
			    103 3739
			    103 3736
			    108 3733
			    105 3729
			    103 3723
			    108 3721
			    103 3717
			    103 3714
			    110 3707
			    108 3702
			    105 3697
			    105 3692
			    103 3687
			    105 3674
			    105 3672
			    108 3671
			    110 3671
			    108 3669
			    113 3667
			    115 3666
			    108 3659
			    110 3648
			    113 3590
			    115 3550
			    115 3500 >;
		};

		bat_notify: bat_notify {
			compatible = "mediatek,bat_notify";
		};

		bat_comm: bat_comm {
			compatible = "mediatek,battery";
			/* cust_charging.h */
			/* stop charging while in talking mode */
			stop_charging_in_takling = <1 >;
			talking_recharge_voltage = <3800 >;
			talking_sync_time = <60 >;

			/* Battery Temperature Protection */
			mtk_temperature_recharge_support = <1 >;
			max_charge_temperature = <50 >;
			max_charge_temperature_minus_x_degree = <47 >;
			min_charge_temperature = <0 >;
			min_charge_temperature_plus_x_degree = <6 >;
			err_charge_temperature = <0xff >;

			/* Linear Charging Threshold */
			v_pre2cc_thres = <3400 >;	/* unit: mV */
			v_cc2topoff_thres = <4050 >;
			recharging_voltage = <4110 >;
			charging_full_current = <100 >;	/* unit: mA */

			/* Charging Current Setting */
			config_usb_if = <0 >;
			usb_charger_current_suspend = <0 >;	/* Unit: 0.01 mA */
			usb_charger_current_unconfigured = <7000 >;	/* Unit: 0.01 mA */
			usb_charger_current_configured = <50000 >;	/* Unit: 0.01 mA */
			usb_charger_current = <50000 >;	/* Unit: 0.01 mA */
			ac_charger_current = <100000 >;	/* Unit: 0.01 mA */
			/* ac_charger_current = <80000 >; */
			non_std_ac_charger_current = <50000 >;	/* Unit: 0.01 mA */
			charging_host_charger_current = <65000 >;	/* Unit: 0.01 mA */
			apple_0_5a_charger_current = <50000 >;	/* Unit: 0.01 mA */
			apple_1_0a_charger_current = <65000 >;	/* Unit: 0.01 mA */
			apple_2_1a_charger_current = <80000 >;	/* Unit: 0.01 mA */

			/* charger error check */
			bat_low_temp_protect_enable = <0 >;
			v_charger_enable = <0 >;	/* 1:on , 0:off */
			/*v_charger_max = <10500 >;*/	/* unit: mV */
			 v_charger_max = <6500 >;
			v_charger_min = <4400 >;

			/*  Tracking TIME */
			onehundred_percent_tracking_time = <10 >;	/* Unit: second */
			npercent_tracking_time = <20 >;	/* Unit: second */
			sync_to_real_tracking_time = <60 >;	/* Unit: second */
			v_0percent_tracking = <3550 >;	/* Unit: mV */

			/* High battery support */
			high_battery_voltage_support = <1 >;

			/* Pump Express support
			mtk_pump_express_plus_support = <1 >;
			ta_start_battery_soc = <1 >;
			ta_stop_battery_soc = <95 >;
			ta_ac_9v_input_current = <200000 >;
			ta_ac_7v_input_current = <200000 >;
			ta_ac_charging_current = <250000 >;
			ta_9v_support = <1 >;*/
		};

		mdcldma:mdcldma@1000A000 {
			compatible = "mediatek,mdcldma";
			reg =	<0x1000A000 0x1000>, /*AP_CLDMA_AO*/
				<0x1000B000 0x1000>, /*MD_CLDMA_AO*/
				<0x1021A000 0x1000>, /*AP_CLDMA_PDN*/
				<0x1021B000 0x1000>, /*MD_CLDMA_PDN*/
				<0x1020A000 0x1000>, /*AP_CCIF_BASE*/
				<0x1020B000 0x1000>; /*MD_CCIF_BASE*/
			interrupts =	<GIC_SPI 145 IRQ_TYPE_LEVEL_HIGH>, /*IRQ_CLDMA*/
					<GIC_SPI 140 IRQ_TYPE_LEVEL_LOW>, /*IRQ_CCIF*/
					<GIC_SPI 221 IRQ_TYPE_EDGE_FALLING>; /*IRQ_MDWDT*/
			mediatek,md_id = <0>;
			mediatek,cldma_capability = <2>;
			mediatek,md_smem_size = <0x10000>; /* md share memory size */
		};

		dbgapb_base@1011A000{
			compatible = "mediatek,dbgapb_base";
			reg = <0x1011A000 0x100>;/* MD debug register */
		};

		ssw:simswitch@0 {
			compatible = "mediatek,sim_switch";
			pinctrl-names =	"default",
					"hot_plug_mode1",
					"hot_plug_mode2",
					"two_sims_bound_to_md1",
					"sim1_md3_sim2_md1";
			pinctrl-0 = <&ssw_default>;
			pinctrl-1 = <&ssw_hot_plug_mode1>;
			pinctrl-2 = <&ssw_hot_plug_mode2>;
			pinctrl-3 = <&ssw_two_sims_bound_to_md1>;
			pinctrl-4 = <&ssw_sim1_md3_sim2_md1>;
		};

		DNL3_XGPT64@0x1000C000 {
			compatible = "mediatek,DNL3_XGPT64";
			reg = <0x1000C000 0x1000>;
			interrupts = <0 159 0x8>;
		};

		MCUCFG@0x10200000 {
			compatible = "mediatek,MCUCFG";
			reg = <0x10200000 0x200>;
			interrupts = <0 0 0x8>;
		};

		mcucfg: mcucfg@10200000 {
			compatible = "mediatek,mt6735-mcucfg";
			reg = <0x10200000 0x200>;
			interrupts = <GIC_SPI 71 IRQ_TYPE_LEVEL_HIGH>;
		};

		RSVD@0x10200200 {
			compatible = "mediatek,RSVD";
			reg = <0x10200200 0x200>;
		};

		MCUSYS_MISCCFG@0x10200400 {
			compatible = "mediatek,MCUSYS_MISCCFG";
			reg = <0x10200400 0x200>;
		};

		MCUSYS_MCUCFG@0x10200600 {
			compatible = "mediatek,MCUSYS_MCUCFG";
			reg = <0x10200600 0xa00>;
		};

		INFRACFG@0x10201000 {
			compatible = "mediatek,INFRACFG";
			reg = <0x10201000 0x1000>;
		};

		SRAMROM@0x10202000 {
			compatible = "mediatek,SRAMROM";
			reg = <0x10202000 0x1000>;
		};

		EMI@0x10203000 {
			compatible = "mediatek,EMI";
			reg = <0x10203000 0x1000>;
			interrupts = <0 136 0x4>;
		};

		sys_cirq: sys_cirq@10204000 {
			compatible = "mediatek,mt6735-sys_cirq";
			reg = <0x10204000 0x1000>;
			interrupts = <GIC_SPI 231 IRQ_TYPE_LEVEL_LOW>;
			mediatek,cirq_num = <159>;
			mediatek,spi_start_offset = <72>;
		};

		m4u@10205000 {
			cell-index = <0>;
			compatible = "mediatek,m4u";
			reg = <0x10205000 0x1000>;
			interrupts = <GIC_SPI 146 IRQ_TYPE_LEVEL_LOW>;
		};

		EFUSEC@10206000 {
			compatible = "mediatek,EFUSEC";
			reg = <0x10206000 0x1000>;
		};

		DEVAPC@10207000 {
			compatible = "mediatek,DEVAPC";
			reg = <0x10207000 0x1000>;
			interrupts = <GIC_SPI 134 IRQ_TYPE_LEVEL_LOW>;
		};

		bus_dbg@10208000 {
			compatible = "mediatek,bus_dbg-v1";
			reg = <0x10208000 0x1000>;
			interrupts = <GIC_SPI 137 IRQ_TYPE_LEVEL_LOW>;
		};

		APMIXED@0x10209000 {
			compatible = "mediatek,APMIXED";
			reg = <0x10209000 0x1000>;
		};


		RSVD@0x1020C000 {
			compatible = "mediatek,RSVD";
			reg = <0x1020C000 0x1000>;
		};

		INFRA_MBIST@0x1020D000 {
			compatible = "mediatek,INFRA_MBIST";
			reg = <0x1020D000 0x1000>;
		};

		TRNG@0x1020F000 {
			compatible = "mediatek,TRNG";
			reg = <0x1020F000 0x1000>;
			interrupts = <0 141 0x8>;
		};

		CKSYS@0x10210000 {
			compatible = "mediatek,CKSYS";
			reg = <0x10210000 0x1000>;
		};

		MIPI_RX_ANA_CSI0@0x10215800 {
			compatible = "mediatek,MIPI_RX_ANA_CSI0";
			reg = <0x10215800 0x400>;
		};

		MIPI_RX_ANA_CSI1@0x10215C00 {
			compatible = "mediatek,MIPI_RX_ANA_CSI1";
			reg = <0x10215C00 0x400>;
		};

		gcpu@10216000 {
			compatible = "mediatek,gcpu";
			reg = <0x10216000 0x1000>;
			interrupts = <GIC_SPI 150 IRQ_TYPE_LEVEL_LOW>;
		};

		gce@10217000 {
			compatible = "mediatek,gce";
			reg = <0x10217000 0xc00>;
			interrupts = <GIC_SPI 151 IRQ_TYPE_LEVEL_LOW>,
						<GIC_SPI 148 IRQ_TYPE_LEVEL_LOW>;
			disp_mutex_reg = <0x14015000 0x1000>;
			g3d_config_base = <0x13000000 0 0xffff0000>;
			mmsys_config_base = <0x14000000 1 0xffff0000>;
			disp_dither_base = <0x14010000 2 0xffff0000>;
			mm_na_base = <0x14020000 3 0xffff0000>;
			imgsys_base = <0x15000000 4 0xffff0000>;
			vdec_gcon_base = <0x16000000 5 0xffff0000>;
			venc_gcon_base = <0x17000000 6 0xffff0000>;
			conn_peri_base = <0x18000000 7 0xffff0000>;
			topckgen_base = <0x10000000 8 0xffff0000>;
			kp_base = <0x10010000 9 0xffff0000>;
			scp_sram_base = <0x10020000 10 0xffff0000>;
			infra_na3_base = <0x10030000 11 0xffff0000>;
			infra_na4_base = <0x10040000 12 0xffff0000>;
			scp_base = <0x10050000 13 0xffff0000>;
			mcucfg_base = <0x10200000 14 0xffff0000>;
			gcpu_base = <0x10210000 15 0xffff0000>;
			usb0_base = <0x11200000 16 0xffff0000>;
			usb_sif_base = <0x11210000 17 0xffff0000>;
			audio_base = <0x11220000 18 0xffff0000>;
			msdc0_base = <0x11230000 19 0xffff0000>;
			msdc1_base = <0x11240000 20 0xffff0000>;
			msdc2_base = <0x11250000 21 0xffff0000>;
			msdc3_base = <0x11260000 22 0xffff0000>;
			pwm_sw_base = <0x1100E000 99 0xfffff000>;
			mdp_rdma0_sof = <0>;
			mdp_rsz0_sof = <1>;
			mdp_rsz1_sof = <2>;
			mdp_tdshp_sof = <3>;
			mdp_wdma_sof = <4>;
			mdp_wrot_sof = <5>;
			disp_ovl0_sof = <6>;
			disp_rdma0_sof = <8>;
			disp_rdma1_sof = <9>;
			disp_wdma0_sof = <10>;
			disp_ccorr_sof = <11>;
			disp_color_sof = <12>;
			disp_aal_sof = <13>;
			disp_gamma_sof = <14>;
			disp_dither_sof = <15>;
			disp_pwm0_sof = <17>;
			mdp_rdma0_frame_done = <18>;
			mdp_rsz0_frame_done = <19>;
			mdp_rsz1_frame_done = <20>;
			mdp_tdshp_frame_done = <21>;
			mdp_wdma_frame_done = <22>;
			mdp_wrot_write_frame_done = <23>;
			mdp_wrot_read_frame_done = <24>;
			disp_ovl0_frame_done = <25>;
			disp_rdma0_frame_done = <27>;
			disp_rdma1_frame_done = <28>;
			disp_wdma0_frame_done = <29>;
			disp_ccorr_frame_done = <30>;
			disp_color_frame_done = <31>;
			disp_aal_frame_done = <32>;
			disp_gamma_frame_done = <33>;
			disp_dither_frame_done = <34>;
			disp_dpi0_frame_done = <36>;
			disp_dsi0_frame_done = <37>;
			stream_done_0 = <38>;
			stream_done_1 = <39>;
			stream_done_2 = <40>;
			stream_done_3 = <41>;
			stream_done_4 = <42>;
			stream_done_5 = <43>;
			stream_done_6 = <44>;
			stream_done_7 = <45>;
			stream_done_8 = <46>;
			stream_done_9 = <47>;
			buf_underrun_event_0 = <48>;
			buf_underrun_event_1 = <49>;
			dsi0_te_event = <50>;
			isp_frame_done_p2_1 = <66>;
			isp_frame_done_p2_0 = <67>;
			seninf_cam0_fifo_full = <73>;
			apxgpt2_count = <0x10004028>;
		};
		lcm_mode: lcm_mode {
			compatible = "mediatek,lcm_mode";
		};
		smi_larb0@14016000 {
			compatible = "mediatek,smi_larb0";
			reg = <0x14016000 0x1000>;
			interrupts = <GIC_SPI 176 IRQ_TYPE_LEVEL_LOW>;
		};

		smi_larb2@15001000 {
			compatible = "mediatek,smi_larb2";
			reg = <0x15001000 0x1000>;
			interrupts = <GIC_SPI 178 IRQ_TYPE_LEVEL_LOW>;
		};

		smi_common@14017000 {
			compatible = "mediatek,smi_common";
			reg = <0x14017000 0x1000>,  /* SMI_COMMON_EXT */
				<0x14016000 0x1000>,  /* LARB 0 */
				<0x16010000 0x1000>,  /* LARB 1 */
				<0x15001000 0x1000>;  /* LARB 2 */
		};

		smi_larb1@16010000 {
			compatible = "mediatek,smi_larb1";
			reg = <0x16010000 0x10000>;
			interrupts = <GIC_SPI 177 IRQ_TYPE_LEVEL_LOW>;
		};

		cqdma@10217c00 {
			compatible = "mediatek,cqdma";
			reg = <0x10217c00 0x400>;
			interrupts = <GIC_SPI 138 IRQ_TYPE_LEVEL_LOW>;
			nr_channel = <1>;
		};

		AP_CCIF1@0x10218000 {
			compatible = "mediatek,AP_CCIF1";
			reg = <0x10218000 0x1000>;
			interrupts = <0 139 0x4>;
		};

		MD_CCIF1@0x10219000 {
			compatible = "mediatek,MD_CCIF1";
			reg = <0x10219000 0x1000>;
		};

		INFRA_MD@0x1021C000 {
			compatible = "mediatek,INFRA_MD";
			reg = <0x1021C000 0x1000>;
		};

		DBGAPB@0x10400000 {
			compatible = "mediatek,DBGAPB";
			reg = <0x10400000 0xc00000>;
			interrupts = <0 132 0x8>;
		};

		DEBUGTOP_CA7L@0x10800000 {
			compatible = "mediatek,DEBUGTOP_CA7L";
			reg = <0x10800000 0x400000>;
		};

		DEBUGTOP_MD1@0x10450000 {
			compatible = "mediatek,DEBUGTOP_MD1";
			reg = <0x10450000 0x20000>;
		};

		DEBUGTOP_MD2@0x10470000 {
			compatible = "mediatek,DEBUGTOP_MD2";
			reg = <0x10470000 0x10000>;
		};

		CA9@0x10220000 {
			compatible = "mediatek,CA9";
			reg = <0x10220000 0x8000>;
		};

		cpu_dbgapb: cpu_dbgapb {
			compatible = "mediatek,hw_dbg";
			num = <4>;
			reg =  <0x10810000 0x1000
				0x10910000 0x1000
				0x10A10000 0x1000
				0x10B10000 0x1000>;
		};

		ap_dma:dma@11000000 {
			compatible = "mediatek,ap_dma";
			reg = <0x11000000 0x1000>;
			interrupts = <0 97 0x8>;
		};

		AP_DMA_IRDA@0x11000100 {
			compatible = "mediatek,AP_DMA_IRDA";
			reg = <0x11000100 0x80>;
			interrupts = <0 98 0x8>;
		};

		auxadc: adc_hw@11001000 {
			compatible = "mediatek,mt6735-auxadc";
			reg = <0x11001000 0x1000>;
			interrupts = <GIC_SPI 76 IRQ_TYPE_EDGE_FALLING>;
		};

		PWM@0x11006000 {
			compatible = "mediatek,PWM";
			reg = <0x11006000 0x1000>;
			interrupts = <0 77 0x8>;
		};
		syscfg_pctl_a: syscfg_pctl_a@0x10211000 {
			compatible = "mediatek,mt6735-pctl-a-syscfg", "syscon";
			reg = <0x10211000 0x1000>;
		};

		pio: pinctrl@0x10211000 {
			compatible = "mediatek,mt6735-pinctrl";
			reg = <0x10211000 0x1000>;
			mediatek,pctl-regmap = <&syscfg_pctl_a>;
			pins-are-numbered;
			gpio-controller;
			#gpio-cells = <2>;
		};

		i2c0:i2c@11007000 {
			compatible = "mediatek,mt6735m-i2c";
			cell-index = <0>;
			reg = <0x11007000 0x1000>;
			interrupts = <GIC_SPI 84 IRQ_TYPE_LEVEL_LOW>,
						<GIC_SPI 99 IRQ_TYPE_LEVEL_LOW>;
			def_speed = <100>;
		};

		i2c1:i2c@11008000 {
			compatible = "mediatek,mt6735m-i2c";
			cell-index = <1>;
			reg = <0x11008000 0x1000>;
			interrupts = <GIC_SPI 85 IRQ_TYPE_LEVEL_LOW>,
						<GIC_SPI 100 IRQ_TYPE_LEVEL_LOW>;
			def_speed = <100>;
		};

		i2c2:i2c@11009000 {
			compatible = "mediatek,mt6735m-i2c";
			cell-index = <2>;
			reg = <0x11009000 0x1000>;
			interrupts = <GIC_SPI 86 IRQ_TYPE_LEVEL_LOW>,
						<GIC_SPI 101 IRQ_TYPE_LEVEL_LOW>;
			def_speed = <100>;
		};

		i2c3:i2c@1100f000 {
			compatible = "mediatek,mt6735m-i2c";
			cell-index = <3>;
			reg = <0x1100f000 0x1000>;
			interrupts = <GIC_SPI 87 IRQ_TYPE_LEVEL_LOW>,
						<GIC_SPI 102 IRQ_TYPE_LEVEL_LOW>;
			def_speed = <100>;
		};

				G3D_CONFIG@0x13000000 {
						compatible = "mediatek,G3D_CONFIG";
						reg = <0x13000000 0x1000>;
				};


				IMGSYS@0x15000000 {
						compatible = "mediatek,IMGSYS";
						reg = <0x15000000 0x1000>;
				};

		SPI1@0x1100A000 {
			cell-index = <0>;
			spi-padmacro = <0>;
			compatible = "mediatek,SPI1";
			reg = <0x1100A000 0x1000>;
			interrupts = <0 118 0x8>;
		};

		touch: touch@ {
			compatible = "mediatek,mt6735-touch",
						"mediatek,mt6735m-touch";
			vtouch-supply = <&mt_pmic_vgp1_ldo_reg>;
		};

		accdet: accdet@ {
			compatible = "mediatek,mt6735-accdet",
						"mediatek,mt6735m-accdet";
		};

		THERM_CTRL@0x1100B000 {
			compatible = "mediatek,THERM_CTRL";
			reg = <0x1100B000 0x1000>;
			interrupts = <0 78 0x8>;
		};

		ptp_fsm@1100b000 {
			compatible = "mediatek,ptp_fsm_v1";
			reg = <0x1100b000 0x1000>;
			interrupts = <GIC_SPI 125 IRQ_TYPE_LEVEL_LOW>;
		};

		AP_DMA_BTIF_TX@0x11000780 {
			compatible = "mediatek,AP_DMA_BTIF_TX";
			reg = <0x11000780 0x80>;
			interrupts = <0 111 0x8>;
		};

		AP_DMA_BTIF_RX@0x11000800 {
			compatible = "mediatek,AP_DMA_BTIF_RX";
			reg = <0x11000800 0x80>;
			interrupts = <0 112 0x8>;
		};

		BTIF@0x1100C000 {
			compatible = "mediatek,BTIF";
			reg = <0x1100C000 0x1000>;
			interrupts = <0 90 0x8>;
		};

		/* NFC start */
		nfc:nfc@0 {
			compatible = "mediatek,nfc-gpio-v2";
			gpio-ven = <4>;
			gpio-rst = <3>;
			gpio-eint = <1>;
			gpio-irq = <2>;
		};
		/* NFC end */

		gps {
			compatible = "mediatek,gps";
		};

		btcvsd@10000000 {
			compatible = "mediatek,audio_bt_cvsd";
			/*INFRA MISC, conn_bt_cvsd_mask, cvsd_mcu_read, write, packet_indicator*/
			offset = <0x700 0x800 0xfd0 0xfd4 0xfd8>;
			reg = <0x10000000 0x1000>, /*AUDIO_INFRA_BASE_PHYSICAL*/
				<0x18000000 0x10000>, /*PKV_PHYSICAL_BASE*/
				<0x18080000 0x8000>; /*SRAM_BANK2*/
			interrupts = <GIC_SPI 228 IRQ_TYPE_LEVEL_LOW>;
		};

		wifi@180F0000 {
			compatible = "mediatek,wifi";
			reg = <0x180F0000 0x005c>;
			interrupts = <GIC_SPI 226 IRQ_TYPE_LEVEL_LOW>;
		};

		NFI@0x1100D000 {
			compatible = "mediatek,NFI";
			reg = <0x1100D000 0x1000>;
			interrupts = <0 96 0x8>;
		};

		DISP_PWM0@0x1100E000 {
			compatible = "mediatek,DISP_PWM0";
			reg = <0x1100E000 0x1000>;
		};

		IRDA@0x11010000 {
			compatible = "mediatek,IRDA";
			reg = <0x11010000 0x1000>;
		};

		usb0:usb20@11200000 {
			compatible = "mediatek,mt6735-usb20";
			cell-index = <0>;
			reg = <0x11200000 0x10000>,
						<0x11210000 0x10000>;
			interrupts = <0 72 0x8>;
			mode = <2>;
			multipoint = <1>;
			dyn_fifo = <1>;
			soft_con = <1>;
			dma = <1>;
			num_eps = <16>;
			dma_channels = <8>;
			drvvbus_gpio = <83 2>;
		};

		audio@11220000 {
			compatible = "mediatek,audio";
			reg = <0x11220000 0x10000>;
			interrupts = <GIC_SPI 144 IRQ_TYPE_LEVEL_LOW>;
		};

		audgpio:mt_soc_dl1_pcm@11220000 {
			compatible = "mediatek,mt-soc-dl1-pcm";
			reg = <0x11220000 0x1000>;
			interrupts = <GIC_SPI 144 IRQ_TYPE_LEVEL_LOW>;
			audclk-gpio = <143 0>;
			audmiso-gpio = <144 0>;
			audmosi-gpio = <145 0>;
			vowclk-gpio = <148 0>;
			extspkamp-gpio = <20 0>;
			i2s1clk-gpio = <80 0>;
			i2s1dat-gpio = <78 0>;
			i2s1mclk-gpio = <9 0>;
			i2s1ws-gpio = <79 0>;
		};

		mt_soc_ul1_pcm@11220000 {
			compatible = "mediatek,mt_soc_pcm_capture";
		};

		mt_soc_voice_md1@11220000 {
			compatible = "mediatek,mt_soc_pcm_voice_md1";
		};

		mt_soc_hdmi_pcm@11220000 {
			compatible = "mediatek,mt_soc_pcm_hdmi";
		};

		mt_soc_uldlloopback_pcm@11220000 {
			compatible = "mediatek,mt_soc_pcm_uldlloopback";
		};

		mt_soc_i2s0_pcm@11220000 {
			compatible = "mediatek,mt_soc_pcm_dl1_i2s0";
		};

		mt_soc_mrgrx_pcm@11220000 {
			compatible = "mediatek,mt_soc_pcm_mrgrx";
		};

		mt_soc_mrgrx_awb_pcm@11220000 {
			compatible = "mediatek,mt_soc_pcm_mrgrx_awb";
		};

		mt_soc_fm_i2s_pcm@11220000 {
			compatible = "mediatek,mt_soc_pcm_fm_i2s";
		};

		mt_soc_fm_i2s_awb_pcm@11220000 {
			compatible = "mediatek,mt_soc_pcm_fm_i2s_awb";
		};

		mt_soc_i2s0dl1_pcm@11220000 {
			compatible = "mediatek,mt_soc_pcm_dl1_i2s0Dl1";
		};

		mt_soc_dl1_awb_pcm@11220000 {
			compatible = "mediatek,mt_soc_pcm_dl1_awb";
		};

		mt_soc_voice_md1_bt@11220000 {
			compatible = "mediatek,mt_soc_pcm_voice_md1_bt";
		};

		mt_soc_voip_bt_out@11220000 {
			compatible = "mediatek,mt_soc_pcm_dl1_bt";
		};

		mt_soc_voip_bt_in@11220000 {
			compatible = "mediatek,mt_soc_pcm_bt_dai";
		};

		mt_soc_tdmrx_pcm@11220000 {
			compatible = "mediatek,mt_soc_tdm_capture";
		};

		mt_soc_fm_mrgtx_pcm@11220000 {
			compatible = "mediatek,mt_soc_pcm_fmtx";
		};

		mt_soc_ul2_pcm@11220000 {
			compatible = "mediatek,mt_soc_pcm_capture2";
		};

		mt_soc_i2s0_awb_pcm@11220000 {
			compatible = "mediatek,mt_soc_pcm_i2s0_awb";
		};

		mt_soc_voice_md2@11220000 {
			compatible = "mediatek,mt_soc_pcm_voice_md2";
		};

		mt_soc_routing_pcm@11220000 {
			compatible = "mediatek,mt_soc_pcm_routing";
			i2s1clk-gpio = <7 6>;
			i2s1dat-gpio = <5 6>;
			i2s1mclk-gpio = <9 6>;
			i2s1ws-gpio = <6 6>;
		};

		mt_soc_voice_md2_bt@11220000 {
			compatible = "mediatek,mt_soc_pcm_voice_md2_bt";
		};

		mt_soc_hp_impedance_pcm@11220000 {
			compatible = "mediatek,Mt_soc_pcm_hp_impedance";
		};

		mt_soc_codec_name@11220000 {
			compatible = "mediatek,mt_soc_codec_63xx";
		};

		mt_soc_dummy_pcm@11220000 {
			compatible = "mediatek,mt_soc_pcm_dummy";
		};

		mt_soc_codec_dummy_name@11220000 {
			compatible = "mediatek,mt_soc_codec_dummy";
		};

		mt_soc_routing_dai_name@11220000 {
			compatible = "mediatek,mt_soc_dai_routing";
		};

		mt_soc_dai_name@11220000 {
			compatible = "mediatek,mt_soc_dai_stub";
		};

		mt_soc_offload_gdma@11220000 {
			compatible = "mediatek,mt_soc_pcm_offload_gdma";
		};

		mt_soc_dl2_pcm@11220000 {
			compatible = "mediatek,mt_soc_pcm_dl2";
		};

		USB1@0x11260000 {
			compatible = "mediatek,USB1";
			reg = <0x11260000 0x10000>;
			interrupts = <0 73 0x8>;
		};

		MSDC3@0x11260000 {
			compatible = "mediatek,MSDC3";
			reg = <0x11260000 0x10000>;
		};

		WCN_AHB@0x11270000 {
			compatible = "mediatek,WCN_AHB";
			reg = <0x11270000 0x10000>;
			interrupts = <0 228 0x8>;
		};

		MDPERIPHERALS@0x20000000 {
			compatible = "mediatek,MD PERIPHERALS";
			reg = <0x20000000 0x0>;
		};

		MD2PERIPHERALS@0x30000000 {
			compatible = "mediatek,MD2 PERIPHERALS";
			reg = <0x30000000 0x0>;
		};

		C2KPERIPHERALS@0x38000000 {
			compatible = "mediatek,C2K PERIPHERALS";
			reg = <0x38000000 0x0>;
		};

		MFGCFG@0x13000000 {
			compatible = "mediatek,MFGCFG";
			reg = <0x13000000 0x1000>;
			interrupts = <0 210 0x8>;
		};

		MALI@0x13040000 {
			compatible = "arm,malit720", "arm,mali-t72x", "arm,malit7xx", "arm,mali-midgard";
			reg = <0x13040000 0x4000>;
			interrupts = <0 212 0x8>, <0 211 0x8>, <0 210 0x8>;
			interrupt-names = "JOB", "MMU", "GPU";
			clock-frequency = <450000000>;
		};

		mmsys_config@14000000 {
			compatible = "mediatek,mmsys_config";
			reg = <0x14000000 0x1000>;
			interrupts = <GIC_SPI 206 IRQ_TYPE_LEVEL_LOW>;
		};

		mdp_rdma@14001000 {
			compatible = "mediatek,mdp_rdma";
			reg = <0x14001000 0x1000>;
			interrupts = <GIC_SPI 187 IRQ_TYPE_LEVEL_LOW>;
		};

		mdp_rsz0@14002000 {
			compatible = "mediatek,mdp_rsz0";
			reg = <0x14002000 0x1000>;
			interrupts = <GIC_SPI 188 IRQ_TYPE_LEVEL_LOW>;
		};

		mdp_rsz1@14003000 {
			compatible = "mediatek,mdp_rsz1";
			reg = <0x14003000 0x1000>;
			interrupts = <GIC_SPI 189 IRQ_TYPE_LEVEL_LOW>;
		};

		mdp_wdma@14004000 {
			compatible = "mediatek,mdp_wdma";
			reg = <0x14004000 0x1000>;
			interrupts = <GIC_SPI 191 IRQ_TYPE_LEVEL_LOW>;
		};

		mdp_wrot@14005000 {
			compatible = "mediatek,mdp_wrot";
			reg = <0x14005000 0x1000>;
			interrupts = <GIC_SPI 192 IRQ_TYPE_LEVEL_LOW>;
		};

		mdp_tdshp@14006000 {
			compatible = "mediatek,mdp_tdshp";
			reg = <0x14006000 0x1000>;
			interrupts = <GIC_SPI 190 IRQ_TYPE_LEVEL_LOW>;
		};

		DISPSYS@14007000 {
			compatible = "mediatek,DISPSYS";
			reg = <0x14007000 0x1000>,  /*DISP_OVL0      */
				<0 0>,  /*DISP_OVL1     */
				<0x14009000 0x1000>,  /*DISP_RDMA0     */
				<0 0>,  /*DISP_RDMA1     */
				<0x1400b000 0x1000>,  /*DISP_WDMA0     */
				<0x1400c000 0x1000>,  /*DISP_COLOR     */
				<0x1400d000 0x1000>,  /*DISP_CCORR     */
				<0x1400e000 0x1000>,  /*DISP_AAL       */
				<0x1400f000 0x1000>,  /*DISP_GAMMA     */
				<0x14010000 0x1000>,  /*DISP_DITHER    */
				<0 0>,  /*DISP_UFOE      */
				<0x1100e000 0x1000>,  /*DISP_PWM       */
				<0 0>,  /*DISP_WDMA1     */
				<0x14015000 0x1000>,  /*DISP_MUTEX     */
				<0x14012000 0x1000>,  /*DISP_DSI0      */
				<0x14013000 0x1000>,  /*DISP_DPI0      */
				<0x14000000 0x1000>,  /*DISP_CONFIG    */
				<0x14016000 0x1000>,  /*DISP_SMI_LARB0 */
				<0x14017000 0x1000>,  /*DISP_SMI_COMMOM*/
				<0x14018000 0x1000>,      /*MIPITX0,real chip would use this:<0x14017000 0x1000>;*/
				<0x10206000 0x1000>,  /*DISP_CONFIG2*/
				<0x10210000 0x1000>,  /*DISP_CONFIG3*/
				<0x10211a70 0x000C>,  /*DISP_DPI_IO_DRIVING1 */
				<0x10211974 0x000C>,  /*DISP_DPI_IO_DRIVING2 */
				<0x10211b70 0x000C>,  /*DISP_DPI_IO_DRIVING3 */
				<0x10206044 0x000C>,  /*DISP_DPI_USE */
				<0x10206514 0x000C>,  /*DISP_DPI_USE_PERMISSION */
				<0x10206558 0x000C>,  /*DISP_DPI_USE_KEY */
				<0x102100a0 0x1000>,  /*DISP_TVDPLL_CFG6 */
				<0x10209260 0x1000>,  /*DISP_TVDPLL_CON0 */
				<0x10209264 0x1000>,  /*DISP_TVDPLL_CON1 */
				<0 0>,  /*DISP_OD      */
				<0x10209000 0x1000>;  /*DISP_VENCPLL      */

			interrupts = <0 193 8>, /*DISP_OVL0 */
				 <0 0 8>, /*DISP_OVL1 */
				 <0 195 8>, /*DISP_RDMA0 */
				 <0 0 8>, /*DISP_RDMA1 */
				 <0 197 8>, /*DISP_WDMA0 */
				 <0 198 8>, /*DISP_COLOR */
				 <0 199 8>, /*DISP_CCORR */
				 <0 200 8>, /*DISP_AAL */
				 <0 201 8>, /*DISP_GAMMA */
				 <0 202 8>, /*DISP_DITHER */
				 <0 0 8>, /*DISP_UFOE */
				 <0 117 8>, /*DISP_PWM */
				 <0 0 8>, /*DISP_WDMA1 */
				 <0 186 8>, /*DISP_MUTEX */
				 <0 204 8>, /*DISP_DSI0 */
				 <0 205 8>, /*DISP_DPI0 */
				 <0 206 8>, /*DISP_CONFIG, 0 means no IRQ*/
				 <0 176 8>, /*DISP_SMI_LARB0 */
				 <0 0 8>, /*DISP_SMI_COMMOM*/
				 <0 0 8>,      /*MIPITX0,real chip would use this:<0x14017000 0x1000>;*/
				 <0 0 8>,  /*DISP_CONFIG2*/
				 <0 0 8>,  /*DISP_CONFIG3*/
				 <0 0 8>,  /*DISP_DPI_IO_DRIVING */
				 <0 0 8>,  /*DISP_TVDPLL_CFG6 */
				 <0 0 8>,  /*DISP_TVDPLL_CON0 */
				 <0 0 8>,  /*DISP_TVDPLL_CON1 */
				 <0 0 8>,  /*DISP_OD      */
				 <0 0 8>;  /*DISP_VENCPLL      */
				};

		DISP_OVL0@0x14007000 {
			compatible = "mediatek,DISP_OVL0";
			reg = <0x14007000 0x1000>;
			interrupts = <0 193 0x8>;
		};

		DISP_OVL1@0x14008000 {
			compatible = "mediatek,DISP_OVL1";
			reg = <0x14008000 0x1000>;
			interrupts = <0 194 0x8>;
		};

		DISP_RDMA0@0x14009000 {
			compatible = "mediatek,DISP_RDMA0";
			reg = <0x14009000 0x1000>;
			interrupts = <0 195 0x8>;
		};

		DISP_RDMA1@0x1400A000 {
			compatible = "mediatek,DISP_RDMA1";
			reg = <0x1400A000 0x1000>;
			interrupts = <0 196 0x8>;
		};

		gpio@0x10000e00 {
			compatible = "mediatek,fpga_gpio";
			reg = <0x10000e00 0x100>;
		};

		DISP_WDMA0@0x1400B000 {
			compatible = "mediatek,DISP_WDMA0";
			reg = <0x1400B000 0x1000>;
			interrupts = <0 197 0x8>;
		};

		DISP_COLOR@0x1400C000 {
			compatible = "mediatek,DISP_COLOR";
			reg = <0x1400C000 0x1000>;
			interrupts = <0 198 0x8>;
		};

		DISP_CCORR@0x1400D000 {
			compatible = "mediatek,DISP_CCORR";
			reg = <0x1400D000 0x1000>;
			interrupts = <0 199 0x8>;
		};

		DISP_AAL@0x1400E000 {
			compatible = "mediatek,DISP_AAL";
			reg = <0x1400E000 0x1000>;
			interrupts = <0 200 0x8>;
		};

		DISP_GAMMA@0x1400F000 {
			compatible = "mediatek,DISP_GAMMA";
			reg = <0x1400F000 0x1000>;
			interrupts = <0 201 0x8>;
		};

		DISP_DITHER@0x14010000 {
			compatible = "mediatek,DISP_DITHER";
			reg = <0x14010000 0x1000>;
			interrupts = <0 202 0x8>;
		};

		DISP_UFOE@0x14011000 {
			compatible = "mediatek,DISP_UFOE";
			reg = <0x14011000 0x1000>;
			interrupts = <0 203 0x8>;
		};

		DSI0@0x14012000 {
			compatible = "mediatek,DSI0";
			reg = <0x14012000 0x1000>;
			interrupts = <0 204 0x8>;
		};

		DPI0@0x14013000 {
			compatible = "mediatek,DPI0";
			reg = <0x14013000 0x1000>;
			interrupts = <0 205 0x8>;
		};

		DISP_PWM@0x14014000 {
			compatible = "mediatek,DISP_PWM";
			reg = <0x14014000 0x1000>;
		};

		MM_MUTEX@0x14015000 {
			compatible = "mediatek,MM_MUTEX";
			reg = <0x14015000 0x1000>;
			interrupts = <0 186 0x8>;
		};

		met_smi: met_smi@14017000 {
			compatible = "mediatek,met_smi";
			reg = <0x14017000 0x1000>,  /* SMI_COMMON_EXT */
					<0x14016000 0x1000>,  /* LARB 0 */
					<0x16010000 0x1000>,  /* LARB 1 */
					<0x15001000 0x1000>,  /* LARB 2 */
					<0x17001000 0x1000>;  /* LARB 3 */
			/*
			clocks = <&mmsys MM_DISP0_SMI_COMMON>,
						 <&mmsys MM_DISP0_SMI_LARB0>,
						 <&imgsys IMG_IMAGE_LARB2_SMI>,
						 <&vdecsys VDEC0_VDEC>,
						 <&vdecsys VDEC1_LARB>,
						 <&vencsys VENC_LARB>,
						 <&vencsys VENC_VENC>;

			clock-names = "smi-common",
				"smi-larb0",
				"img-larb2",
				"vdec0-vdec",
				"vdec1-larb",
				"venc-larb",
				"venc-venc";
			*/
		};


		MIPI_TX_CONFIG@0x14018000 {
			compatible = "mediatek,MIPI_TX_CONFIG";
			reg = <0x14018000 0x1000>;
		};

								ISPSYS@0x15000000 {
			compatible = "mediatek,ISPSYS";
			reg = <0x15004000 0x9000>,  /*ISP_ADDR      */
				<0x15000000 0x10000>,  /*IMGSYS_CONFIG_ADDR      */
				<0x10215000 0x1000>;  /*MIPI_ANA_ADDR      */
			interrupts = <0 182 0x8>, /* SENINF */
									 <0 183 0x8>; /* CAM0 */
		};
		kd_camera_hw1:kd_camera_hw1@15008000 {
			compatible = "mediatek,camera_hw";
			reg = <0x15008000 0x1000>;  /* SENINF_ADDR */
			vcama-supply = <&mt_pmic_vcama_ldo_reg>;
			vcamd-supply = <&mt_pmic_vcamd_ldo_reg>;
			vcamaf-supply = <&mt_pmic_vcam_af_ldo_reg>;
			vcamio-supply = <&mt_pmic_vcam_io_ldo_reg>;
		};
		kd_camera_hw2:kd_camera_hw2@15008000 {
			compatible = "mediatek,camera_hw2";
			reg = <0x15008000 0x1000>;  /* SENINF_ADDR */
		};
//Modify camera main2 by Droi DXQ start 20170906		
		kd_camera_hw3:kd_camera_hw3@15008000 {
			compatible = "mediatek,camera_hw3";
			reg = <0x15008000 0x1000>;  /* SENINF_ADDR */
		};
//Modify camera main2 by Droi DXQ end 20170906
								/*for sysram dev and pipemgr dev*/
								ISP_SYSR@0x15000000 {
			compatible = "mediatek,ISP_SYSR";
		};
								ISP_PIPEM@0x15000000 {
			compatible = "mediatek,ISP_PIPEM";
		};
		SENINF_TOP@0x15008000 {
			compatible = "mediatek,SENINF_TOP";
			reg = <0x15008000 0x1000>;
			interrupts = <0 182 0x8>;
		};

		CAM@0x15004000 {
			compatible = "mediatek,CAM";
			reg = <0x15004000 0x1000>;
			interrupts = <0 183 0x8>;
		};

		VENC@0x15009000 {
			compatible = "mediatek,VENC";
			reg = <0x15009000 0x1000>;
			interrupts = <0 180 0x8>;
		};

		VDEC@0x1500B000 {
			compatible = "mediatek,VDEC";
			reg = <0x1500B000 0x1000>;
		};
		dsi_te: dsi_te {
			compatible = "mediatek, dsi_te_1-eint";
			status = "disabled";
		};
		JPGENC@0x1500A000 {
			compatible = "mediatek,JPGENC";
			reg = <0x1500A000 0x1000>;
			interrupts = <0 181 0x8>;
		};


		VDEC_GCON@0x16000000 {
			compatible = "mediatek,VDEC_GCON";
			reg = <0x16000000 0x1000>;
		};

		VDEC_FULL_TOP@0x16020000 {
			compatible = "mediatek,VDEC_FULL_TOP";
			reg = <0x16020000 0x10000>;
			interrupts = <0 179 0x8>;
		};

		CHIPID@08000000 {
			compatible = "mediatek,CHIPID";
			reg = <0x08000000 0x0004>,
									<0x08000004 0x0004>,
									<0x08000008 0x0004>,
									<0x0800000C 0x0004>;
		};
		pwm:pwm@11006000 {
			compatible = "mediatek,pwm";
			reg = <0x11006000 0x1000>;
			interrupts = <GIC_SPI 77 IRQ_TYPE_LEVEL_LOW>;
		};
	};
	lcm: lcm {
		compatible = "mediatek,lcm";
	};
		kd_camera_flashlight:kd_camera_flashlight {
			compatible = "mediatek,camera_flashlight";
		};

/* sensor part */
		hwmsensor@0 {
			compatible = "mediatek,hwmsensor";
		};
		gsensor@0 {
			compatible = "mediatek,gsensor";
		};
		alsps:als_ps@0 {
			compatible = "mediatek,als_ps";
		};
		m_acc_pl@0 {
			compatible = "mediatek,m_acc_pl";
		};

		m_alsps_pl@0 {
			compatible = "mediatek,m_alsps_pl";
		};

		m_batch_pl@0 {
			compatible = "mediatek,m_batch_pl";
		};
		batchsensor@0 {
			compatible = "mediatek,batchsensor";
		};
		gyro:gyroscope@0 {
			compatible = "mediatek,gyroscope";
		};
		m_gyro_pl@0 {
			compatible = "mediatek,m_gyro_pl";
		};
		barometer@0 {
			compatible = "mediatek,barometer";
		};
		m_baro_pl@0 {
			compatible = "mediatek,m_baro_pl";
		};
		msensor@0 {
			compatible = "mediatek,msensor";
		};
		m_mag_pl@0 {
			compatible = "mediatek,m_mag_pl";
		};
		orientation@0 {
			compatible = "mediatek,orientation";
	};

/* sensor end */
	MOBICORE {
		compatible = "trustonic,mobicore";
		interrupts = <GIC_SPI 248 IRQ_TYPE_EDGE_RISING>;
	};

	rf_clock_buffer_ctrl:rf_clock_buffer {
		compatible = "mediatek,rf_clock_buffer";
		mediatek,clkbuf-quantity = <4>;
		mediatek,clkbuf-config = <2 1 1 1>;
	};
};
#ifndef CONFIG_OF_RESOLVE
#include <cust.dtsi>
#endif
&eintc {
	pmic@206 {
	compatible = "mediatek, pmic-eint";
	interrupt-parent = <&eintc>;
	interrupts = <206 4>;
	debounce = <206 1000>;
	};
};

&pio {
	ssw_default:ssw0default {
	};

	ssw_hot_plug_mode1:ssw@1 {

		pins_cmd0_dat {
			pins = <PINMUX_GPIO8__FUNC_MD_EINT1>;
		};

		pins_cmd1_dat {
			pins = <PINMUX_GPIO9__FUNC_MD_EINT2>;
		};
	};

	ssw_hot_plug_mode2:ssw@2 {

		pins_cmd0_dat {
			pins = <PINMUX_GPIO8__FUNC_C2K_UIM0_HOT_PLUG_IN>;
		};

		pins_cmd1_dat {
			pins = <PINMUX_GPIO9__FUNC_MD_EINT2>;
		};
	};

	ssw_two_sims_bound_to_md1:ssw@3 {
		pins_cmd0_dat {
			pins = <PINMUX_GPIO163__FUNC_MD_SIM1_SCLK>;
			slew-rate = <1>;
		};

		pins_cmd1_dat {
			pins = <PINMUX_GPIO164__FUNC_MD_SIM1_SRST>;
			slew-rate = <1>;
		};

		pins_cmd2_dat {
			pins = <PINMUX_GPIO165__FUNC_MD_SIM1_SDAT>;
			slew-rate = <0>;
			bias-pull-up = <00>;

		};

		pins_cmd3_dat {
			pins = <PINMUX_GPIO160__FUNC_MD_SIM2_SCLK>;
			slew-rate = <1>;
		};

		pins_cmd4_dat {
			pins = <PINMUX_GPIO161__FUNC_MD_SIM2_SRST>;
			slew-rate = <1>;
		};

		pins_cmd5_dat {
			pins = <PINMUX_GPIO162__FUNC_MD_SIM2_SDAT>;
			slew-rate = <0>;
			bias-pull-up = <00>;
		};
	};

	ssw_sim1_md3_sim2_md1:ssw@4 {
		pins_cmd0_dat {
			pins = <PINMUX_GPIO163__FUNC_UIM0_CLK>;
		};

		pins_cmd1_dat {
			pins = <PINMUX_GPIO164__FUNC_UIM0_RST>;
		};

		pins_cmd2_dat {
			pins = <PINMUX_GPIO165__FUNC_UIM0_IO>;
		};

		pins_cmd3_dat {
			pins = <PINMUX_GPIO160__FUNC_MD_SIM2_SCLK>;
		};

		pins_cmd4_dat {
			pins = <PINMUX_GPIO161__FUNC_MD_SIM2_SRST>;
		};

		pins_cmd5_dat {
			pins = <PINMUX_GPIO162__FUNC_MD_SIM2_SDAT>;
		};
	};
};
/*SSW end*/

/*GPIO standardization CLDMA*/
&mdcldma {
	pinctrl-names = "default", "vsram_output_low", "vsram_output_high", "RFIC0_01_mode", "RFIC0_04_mode";

	pinctrl-0 = <&vsram_default>;
	pinctrl-1 = <&vsram_output_low>;
	pinctrl-2 = <&vsram_output_high>;
	pinctrl-3 = <&RFIC0_01_mode>;
	pinctrl-4 = <&RFIC0_04_mode>;
};

&pio {
	vsram_default: vsram0default {
	};

	vsram_output_low: vsram@1 {
		pins_cmd_dat {
			pins = <PINMUX_GPIO140__FUNC_GPIO140>;
			slew-rate = <1>;
			output-low;
		};
	};

	vsram_output_high: vsram@2 {
		pins_cmd_dat {
			pins = <PINMUX_GPIO140__FUNC_GPIO140>;
			slew-rate = <1>;
			output-high;
		};
	};

	RFIC0_01_mode: clockbuf@1{

		pins_cmd0_dat {
			pins = <PINMUX_GPIO110__FUNC_RFIC0_BSI_EN>;
		};

		pins_cmd1_dat {
			pins = <PINMUX_GPIO111__FUNC_RFIC0_BSI_CK>;
		};

		pins_cmd2_dat {
			pins = <PINMUX_GPIO112__FUNC_RFIC0_BSI_D2>;
		};


		pins_cmd3_dat {
			pins = <PINMUX_GPIO113__FUNC_RFIC0_BSI_D1>;
		};

		pins_cmd4_dat {
			pins = <PINMUX_GPIO114__FUNC_RFIC0_BSI_D0>;
		};
	};

	RFIC0_04_mode: clockbuf@2{

		pins_cmd0_dat {
			pins = <PINMUX_GPIO110__FUNC_SPM_BSI_EN>;
		};

		pins_cmd1_dat {
			pins = <PINMUX_GPIO111__FUNC_SPM_BSI_CLK>;
		};

		pins_cmd2_dat {
			pins = <PINMUX_GPIO112__FUNC_SPM_BSI_D2>;
		};

		pins_cmd3_dat {
			pins = <PINMUX_GPIO113__FUNC_SPM_BSI_D1>;
		};

		pins_cmd4_dat {
			pins = <PINMUX_GPIO114__FUNC_SPM_BSI_D0>;
		};

	};
};
/*CLDMA end*/

#include <trusty.dtsi>
